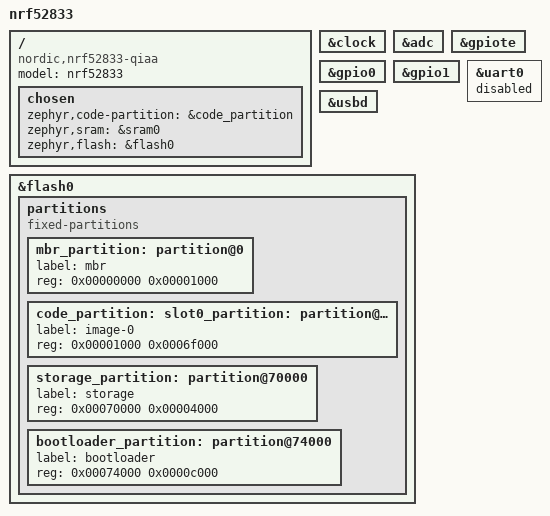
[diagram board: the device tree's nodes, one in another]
/*
 * Copyright (c) 2026 Miguelio
 * SPDX-License-Identifier: MIT
 *
 * Board: E73-2G4M08S1C (nRF52833)
 * - No external 32.768kHz crystal (uses internal RC)
 * - Powered via VDDH from USB (5V)
 */

/dts-v1/;
#include <nordic/nrf52833_qiaa.dtsi>

/ {
	model = "nrf52833";
	compatible = "nordic,nrf52833-qiaa";

	chosen {
		zephyr,code-partition = &code_partition;
		zephyr,sram = &sram0;
		zephyr,flash = &flash0;
	};
};

&clock {
	status = "okay";
};

&adc {
	status = "okay";
};

&gpiote {
	status = "okay";
};

&gpio0 {
	status = "okay";
};

&gpio1 {
	status = "okay";
};

&uart0 {
	status = "disabled";
};

zephyr_udc0: &usbd {
	status = "okay";
};

&flash0 {
    partitions {
        compatible = "fixed-partitions";
        #address-cells = <1>;
        #size-cells = <1>;

        mbr_partition: partition@0 {
            label = "mbr";
            reg = <0x00000000 0x00001000>;
        };

        code_partition: slot0_partition: partition@1000 {
            label = "image-0";
            reg = <0x00001000 0x0006f000>; /* Hasta la 0x70000 */
        };

        storage_partition: partition@70000 {
            label = "storage";
            reg = <0x00070000 0x00004000>; /* 16KB para datos */
        };

        bootloader_partition: partition@74000 {
            label = "bootloader";
            reg = <0x00074000 0x0000c000>; /* 48KB finales */
        };
    };
};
